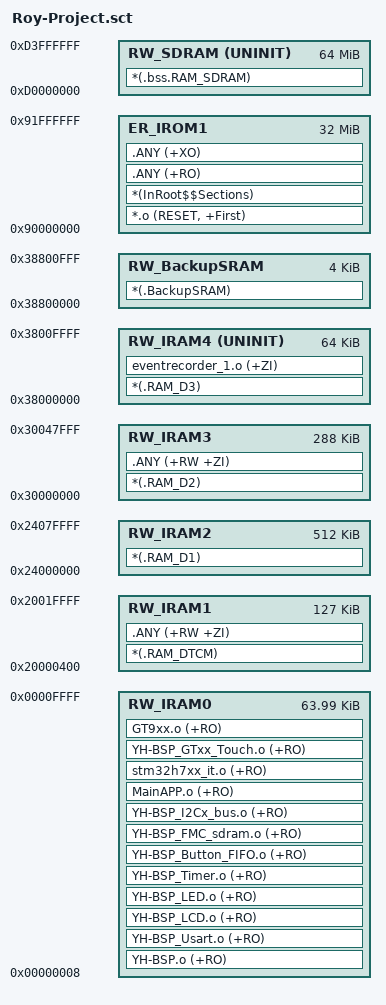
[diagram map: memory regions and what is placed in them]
; *************************************************************
; *** Scatter-Loading Description File generated by uVision ***
; *************************************************************

LR_IROM1 0x90000000 0x02000000  {    ; load region size_region
  ER_IROM1 0x90000000 0x02000000  {  ; load address = execution address
   *.o (RESET, +First)
   *(InRoot$$Sections)
   .ANY (+RO)
   .ANY (+XO)
  }

  ; RW data 64KB ITCM
  RW_IRAM0 0x00000008 0x0000FFF8  {  ; RW data
    YH-BSP.o (+RO)
    YH-BSP_Usart.o (+RO)
    YH-BSP_LCD.o (+RO)
    YH-BSP_LED.o (+RO)
    YH-BSP_Timer.o (+RO)
    YH-BSP_Button_FIFO.o (+RO)
    ;YH-BSP_Beep.o (+RO)
    YH-BSP_FMC_sdram.o (+RO)
    YH-BSP_I2Cx_bus.o (+RO)
    MainAPP.o (+RO)
    stm32h7xx_it.o (+RO)
    YH-BSP_GTxx_Touch.o (+RO)
    GT9xx.o (+RO)
  }

  ; RW data 128KB DTCM
  ;RW_IRAM1 0x20000000 0x00020000  {  ; RW data
  ; .ANY (+RW +ZI)
  ;}

  ; RW data 127KB DTCM
  RW_IRAM1 0x20000400 0x0001FC00  {  ; RW data
   *(.RAM_DTCM)
   .ANY (+RW +ZI)
  }

  ; RW data 512KB AXI SRAM
  RW_IRAM2 0x24000000 0x00080000  {
    *(.RAM_D1)

  }

  ; RW data 128KB SRAM1(0x30000000) + 128KB SRAM2(0x30020000) + 32KB SRAM3(0x30040000)
  RW_IRAM3 0x30000000 0x00048000 {
    *(.RAM_D2)
    .ANY (+RW +ZI)
  }

  ; RW data 64KB SRAM4(0x38000000)
  RW_IRAM4 0x38000000 UNINIT 0x00010000 {
    *(.RAM_D3)
    eventrecorder_1.o (+ZI)
  }

  ; RW data 4KB BackupSRAM(0x38800000)
  RW_BackupSRAM 0x38800000 0x1000 {
    *(.BackupSRAM)

  }

  ; RW data 64MB SDRAM BANK2 (0xD0000000)
  RW_SDRAM 0xD0000000 UNINIT 0x04000000 {
    *(.bss.RAM_SDRAM)
  }
}

